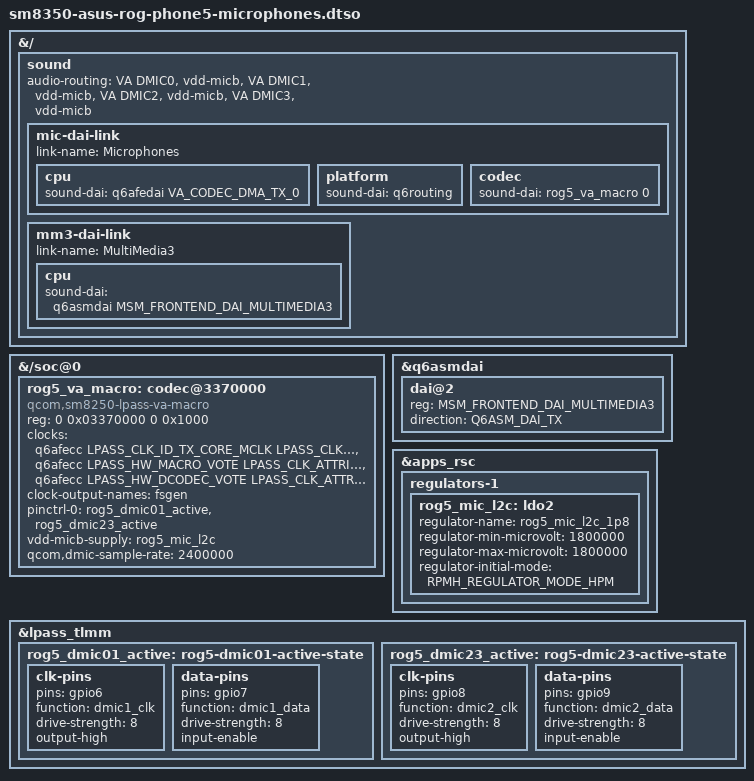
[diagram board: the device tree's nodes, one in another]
// SPDX-License-Identifier: BSD-3-Clause
/*
 * Built-in microphones: four digital mics on the LPASS DMIC pads, LPI
 * gpio6/7 (dmic1_clk/data: DMIC0 and DMIC1 on the two clock edges) and
 * gpio8/9 (dmic2_clk/data: DMIC2, DMIC3), powered from L2C at 1.8 V (stock
 * ZS673KS DT: va-vdd-micb-supply = <&L2C>). gpio12/13 (dmic3) are the SENARY
 * MI2S data lines, as on stock.
 *
 * Stock routes the mics through the Bolero TX macro decimators
 * (TX_CDC_DMA_TX_3), but the DMIC clock generators live in the VA macro's
 * TOP_CSR (stock bolero_dmic_clk_enable writes VA_TOP_CSR_DMICn_CTL for TX
 * captures too) and the mainline TX macro never enables them. The mainline VA
 * macro drives the same DMICs itself (stock routes "VA DMICn" to the same
 * "Digital MicN"), so capture uses VA decimators and VA_CODEC_DMA_TX_0, as on
 * the SM8250 RB5 (also q6afe, same LPI dmic pads). Bolero 2.0's VA register map
 * matches the SM8250 VA macro offset for offset; "qcom,sm8250-lpass-va-macro"
 * also skips the core-ID read, the SoundWire master and the NPL clock, none of
 * which the stock lahaina VA macro uses. MCLK is the TX core clock, as stock
 * (default-clk-id TX_CORE_CLK) and SM8250. Needs kernel patch 0083 so the
 * macro drops its LPASS core votes when idle.
 *
 * Applied before the audio overlay: fdtoverlay prepends new children, so the
 * existing links (MultiMedia1 = PCM 0) keep their device numbers and the
 * capture front end becomes PCM 3.
 */
/dts-v1/;
/plugin/;

#include <dt-bindings/regulator/qcom,rpmh-regulator.h>
#include <dt-bindings/sound/qcom,q6afe.h>
#include <dt-bindings/sound/qcom,q6asm.h>

&{/} {
	sound {
		audio-routing =
			"VA DMIC0", "vdd-micb",
			"VA DMIC1", "vdd-micb",
			"VA DMIC2", "vdd-micb",
			"VA DMIC3", "vdd-micb";

		/* fdtoverlay reverses these: the front end ends up first. */
		mic-dai-link {
			link-name = "Microphones";

			cpu {
				sound-dai = <&q6afedai VA_CODEC_DMA_TX_0>;
			};

			platform {
				sound-dai = <&q6routing>;
			};

			codec {
				sound-dai = <&rog5_va_macro 0>;
			};
		};

		mm3-dai-link {
			link-name = "MultiMedia3";

			cpu {
				sound-dai = <&q6asmdai MSM_FRONTEND_DAI_MULTIMEDIA3>;
			};
		};
	};
};

&{/soc@0} {
	rog5_va_macro: codec@3370000 {
		compatible = "qcom,sm8250-lpass-va-macro";
		reg = <0 0x03370000 0 0x1000>;
		clocks = <&q6afecc LPASS_CLK_ID_TX_CORE_MCLK LPASS_CLK_ATTRIBUTE_COUPLE_NO>,
			 <&q6afecc LPASS_HW_MACRO_VOTE LPASS_CLK_ATTRIBUTE_COUPLE_NO>,
			 <&q6afecc LPASS_HW_DCODEC_VOTE LPASS_CLK_ATTRIBUTE_COUPLE_NO>;
		clock-names = "mclk", "macro", "dcodec";
		#clock-cells = <0>;
		clock-output-names = "fsgen";
		#sound-dai-cells = <1>;

		pinctrl-0 = <&rog5_dmic01_active>, <&rog5_dmic23_active>;
		pinctrl-names = "default";

		vdd-micb-supply = <&rog5_mic_l2c>;
		/* Stock records at 2.4 MHz (qcom,tx-dmic-sample-rate); MCLK/4. */
		qcom,dmic-sample-rate = <2400000>;
	};
};

&q6asmdai {
	dai@2 {
		reg = <MSM_FRONTEND_DAI_MULTIMEDIA3>;
		direction = <Q6ASM_DAI_TX>;
	};
};

&apps_rsc {
	regulators-1 {
		/* Mic bias for all four DMICs; DAPM enables it only while capturing. */
		rog5_mic_l2c: ldo2 {
			regulator-name = "rog5_mic_l2c_1p8";
			regulator-min-microvolt = <1800000>;
			regulator-max-microvolt = <1800000>;
			regulator-initial-mode = <RPMH_REGULATOR_MODE_HPM>;
		};
	};
};

&lpass_tlmm {
	/* Stock dmic01/dmic23 active states (lahaina-lpi.dtsi). */
	rog5_dmic01_active: rog5-dmic01-active-state {
		clk-pins {
			pins = "gpio6";
			function = "dmic1_clk";
			drive-strength = <8>;
			output-high;
		};

		data-pins {
			pins = "gpio7";
			function = "dmic1_data";
			drive-strength = <8>;
			input-enable;
		};
	};

	rog5_dmic23_active: rog5-dmic23-active-state {
		clk-pins {
			pins = "gpio8";
			function = "dmic2_clk";
			drive-strength = <8>;
			output-high;
		};

		data-pins {
			pins = "gpio9";
			function = "dmic2_data";
			drive-strength = <8>;
			input-enable;
		};
	};
};
